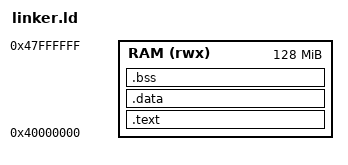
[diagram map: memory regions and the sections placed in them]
ENTRY(_start)

MEMORY
{
    RAM (rwx) : ORIGIN = 0x40000000, LENGTH = 128M
}

SECTIONS
{
    .text :
    {
        KEEP(*(.text.start))
        *(.text*)
        *(.rodata*)
        *(.ARM.extab*)
        *(.ARM.exidx*)
    } > RAM

    .data :
    {
        *(.data*)
    } > RAM

    .bss (NOLOAD) :
    {
        __bss_start__ = .;
        *(.bss*)
        *(COMMON)
        __bss_end__ = .;
    } > RAM

    . = ALIGN(16);
    . += 64K;
    _stack_top = .;
}
